AUTOSAR XML (schema 00049)
package /ISOFT/PlatformComponents/sm/swc
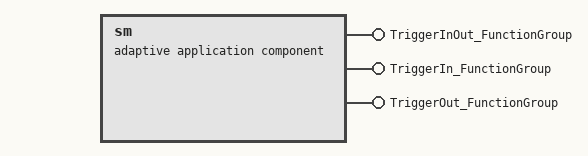
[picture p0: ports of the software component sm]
  adaptive application sw component type sm
    provide port TriggerInOut_FunctionGroup: provided-interface=TriggerInOut_FunctionGroup
    provide port TriggerIn_FunctionGroup: provided-interface=TriggerIn_FunctionGroup
    provide port TriggerOut_FunctionGroup: provided-interface=TriggerOut_FunctionGroup
